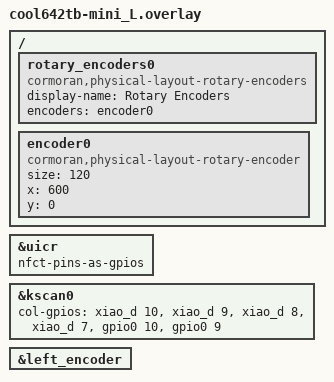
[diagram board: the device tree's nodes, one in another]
#include "cool642tb-mini.dtsi"

&uicr {
    nfct-pins-as-gpios;
};

&kscan0 {
        col-gpios
            = <&xiao_d 10 GPIO_ACTIVE_HIGH>
            , <&xiao_d 9 GPIO_ACTIVE_HIGH> 
            , <&xiao_d 8 GPIO_ACTIVE_HIGH> 
            , <&xiao_d 7 GPIO_ACTIVE_HIGH> 
            , <&gpio0 10 GPIO_ACTIVE_HIGH>
            , <&gpio0 9 GPIO_ACTIVE_HIGH>
            ;
};

&left_encoder {
    status = "okay";
};

/ {
    // ==============================================================================
    // 物理レイアウト: ロータリーエンコーダー (DYA Studio で表示)
    // ==============================================================================
    rotary_encoders0: rotary_encoders0 {
        compatible = "cormoran,physical-layout-rotary-encoders";
        display-name = "Rotary Encoders";  // 必須プロパティ
        encoders = <&encoder0>;
    };

    encoder0: encoder0 {
        compatible = "cormoran,physical-layout-rotary-encoder";
        // linked-device-identifiers は不要（encoder0 には定義されていない）
        size = <120>;        // エンコーダーの表示サイズ (120 = 1.2u 相当)
        x = <600>;           // X 座標 (左側の右端あたり)
        y = <0>;             // Y 座標 (上側)
    };
};
